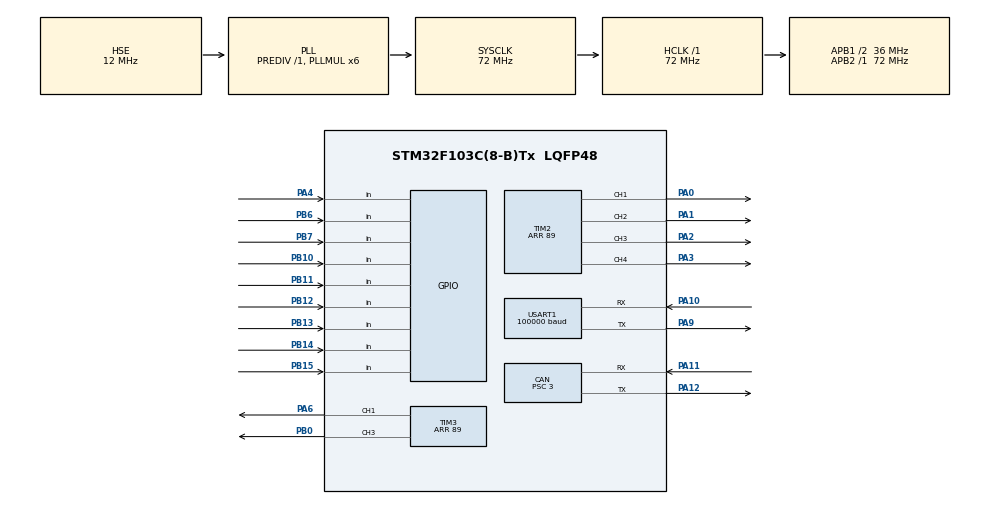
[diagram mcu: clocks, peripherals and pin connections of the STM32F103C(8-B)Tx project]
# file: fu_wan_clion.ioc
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CAN.BS1=CAN_BS1_9TQ
CAN.BS2=CAN_BS2_2TQ
CAN.CalculateBaudRate=999999
CAN.CalculateTimeBit=1000
CAN.CalculateTimeQuantum=83.33333333333334
CAN.Prescaler=3
Dma.Request0=TIM2_CH1
Dma.Request1=TIM2_CH2/CH4
Dma.Request2=TIM2_CH3
Dma.Request3=TIM3_CH1/TRIG
Dma.Request4=TIM3_CH3
Dma.TIM2_CH1.0.Direction=DMA_MEMORY_TO_PERIPH
Dma.TIM2_CH1.0.Instance=DMA1_Channel5
Dma.TIM2_CH1.0.MemDataAlignment=DMA_MDATAALIGN_HALFWORD
Dma.TIM2_CH1.0.MemInc=DMA_MINC_ENABLE
Dma.TIM2_CH1.0.Mode=DMA_NORMAL
Dma.TIM2_CH1.0.PeriphDataAlignment=DMA_PDATAALIGN_HALFWORD
Dma.TIM2_CH1.0.PeriphInc=DMA_PINC_DISABLE
Dma.TIM2_CH1.0.Priority=DMA_PRIORITY_LOW
Dma.TIM2_CH2/CH4.1.Direction=DMA_MEMORY_TO_PERIPH
Dma.TIM2_CH2/CH4.1.Instance=DMA1_Channel7
Dma.TIM2_CH2/CH4.1.MemDataAlignment=DMA_MDATAALIGN_HALFWORD
Dma.TIM2_CH2/CH4.1.MemInc=DMA_MINC_ENABLE
Dma.TIM2_CH2/CH4.1.Mode=DMA_NORMAL
Dma.TIM2_CH2/CH4.1.PeriphDataAlignment=DMA_PDATAALIGN_HALFWORD
Dma.TIM2_CH2/CH4.1.PeriphInc=DMA_PINC_DISABLE
Dma.TIM2_CH2/CH4.1.Priority=DMA_PRIORITY_LOW
Dma.TIM2_CH3.2.Direction=DMA_MEMORY_TO_PERIPH
Dma.TIM2_CH3.2.Instance=DMA1_Channel1
Dma.TIM2_CH3.2.MemDataAlignment=DMA_MDATAALIGN_HALFWORD
Dma.TIM2_CH3.2.MemInc=DMA_MINC_ENABLE
Dma.TIM2_CH3.2.Mode=DMA_NORMAL
Dma.TIM2_CH3.2.PeriphDataAlignment=DMA_PDATAALIGN_HALFWORD
Dma.TIM2_CH3.2.PeriphInc=DMA_PINC_DISABLE
Dma.TIM2_CH3.2.Priority=DMA_PRIORITY_LOW
Dma.TIM3_CH1/TRIG.3.Direction=DMA_MEMORY_TO_PERIPH
Dma.TIM3_CH1/TRIG.3.Instance=DMA1_Channel6
Dma.TIM3_CH1/TRIG.3.MemDataAlignment=DMA_MDATAALIGN_HALFWORD
Dma.TIM3_CH1/TRIG.3.MemInc=DMA_MINC_ENABLE
Dma.TIM3_CH1/TRIG.3.Mode=DMA_NORMAL
Dma.TIM3_CH1/TRIG.3.PeriphDataAlignment=DMA_PDATAALIGN_HALFWORD
Dma.TIM3_CH1/TRIG.3.PeriphInc=DMA_PINC_DISABLE
Dma.TIM3_CH1/TRIG.3.Priority=DMA_PRIORITY_LOW
Dma.TIM3_CH3.4.Direction=DMA_MEMORY_TO_PERIPH
Dma.TIM3_CH3.4.Instance=DMA1_Channel2
Dma.TIM3_CH3.4.MemDataAlignment=DMA_MDATAALIGN_HALFWORD
Dma.TIM3_CH3.4.MemInc=DMA_MINC_ENABLE
Dma.TIM3_CH3.4.Mode=DMA_NORMAL
Dma.TIM3_CH3.4.PeriphDataAlignment=DMA_PDATAALIGN_HALFWORD
Dma.TIM3_CH3.4.PeriphInc=DMA_PINC_DISABLE
Dma.TIM3_CH3.4.Priority=DMA_PRIORITY_LOW
Mcu.Family=STM32F1
Mcu.Name=STM32F103C(8-B)Tx
Mcu.Package=LQFP48
NVIC.DMA1_Channel1_IRQn=true\:0\:0\:false\:false\:true\:false\:true\:true
NVIC.DMA1_Channel2_IRQn=true\:0\:0\:false\:false\:true\:false\:true\:true
NVIC.DMA1_Channel5_IRQn=true\:0\:0\:false\:false\:true\:false\:true\:true
NVIC.DMA1_Channel6_IRQn=true\:0\:0\:false\:false\:true\:false\:true\:true
NVIC.DMA1_Channel7_IRQn=true\:0\:0\:false\:false\:true\:false\:true\:true
NVIC.PriorityGroup=NVIC_PRIORITYGROUP_4
NVIC.TIM4_IRQn=true\:0\:0\:false\:false\:true\:true\:true\:true
NVIC.USART1_IRQn=true\:0\:0\:false\:false\:true\:true\:true\:true
NVIC.USB_LP_CAN1_RX0_IRQn=true\:0\:0\:false\:false\:true\:true\:true\:true
PA0-WKUP.Signal=S_TIM2_CH1_ETR
PA1.Signal=S_TIM2_CH2
PA10.Mode=Asynchronous
PA10.Signal=USART1_RX
PA11.Mode=CAN_Activate
PA11.Signal=CAN_RX
PA12.Mode=CAN_Activate
PA12.Signal=CAN_TX
PA13.Mode=Serial_Wire
PA13.Signal=SYS_JTMS-SWDIO
PA14.Mode=Serial_Wire
PA14.Signal=SYS_JTCK-SWCLK
PA2.Signal=S_TIM2_CH3
PA3.Signal=S_TIM2_CH4
PA4.GPIO_PuPd=GPIO_PULLUP
PA4.Signal=GPIO_Input
PA6.Signal=S_TIM3_CH1
PA9.Mode=Asynchronous
PA9.Signal=USART1_TX
PB0.Signal=S_TIM3_CH3
PB10.GPIO_PuPd=GPIO_PULLUP
PB10.Signal=GPIO_Input
PB11.GPIO_PuPd=GPIO_PULLUP
PB11.Signal=GPIO_Input
PB12.GPIO_PuPd=GPIO_PULLUP
PB12.Signal=GPIO_Input
PB13.GPIO_PuPd=GPIO_PULLUP
PB13.Signal=GPIO_Input
PB14.GPIO_PuPd=GPIO_PULLUP
PB14.Signal=GPIO_Input
PB15.GPIO_PuPd=GPIO_PULLUP
PB15.Signal=GPIO_Input
PB6.GPIO_PuPd=GPIO_PULLUP
PB6.Signal=GPIO_Input
PB7.GPIO_PuPd=GPIO_PULLUP
PB7.Signal=GPIO_Input
PD0-OSC_IN.Mode=HSE-External-Oscillator
PD0-OSC_IN.Signal=RCC_OSC_IN
PD1-OSC_OUT.Mode=HSE-External-Oscillator
PD1-OSC_OUT.Signal=RCC_OSC_OUT
ProjectManager.HeapSize=0x200
ProjectManager.StackSize=0x400
ProjectManager.TargetToolchain=CMake
RCC.AHBFreq_Value=72000000
RCC.APB1CLKDivider=RCC_HCLK_DIV2
RCC.APB1Freq_Value=36000000
RCC.APB1TimFreq_Value=72000000
RCC.APB2Freq_Value=72000000
RCC.APB2TimFreq_Value=72000000
RCC.HCLKFreq_Value=72000000
RCC.HSE_VALUE=12000000
RCC.PLLMUL=RCC_PLL_MUL6
RCC.PLLSourceVirtual=RCC_PLLSOURCE_HSE
RCC.SYSCLKFreq_VALUE=72000000
RCC.SYSCLKSource=RCC_SYSCLKSOURCE_PLLCLK
RCC.USBFreq_Value=72000000
SH.S_TIM2_CH1_ETR.0=TIM2_CH1,PWM Generation1 CH1
SH.S_TIM2_CH2.0=TIM2_CH2,PWM Generation2 CH2
SH.S_TIM2_CH3.0=TIM2_CH3,PWM Generation3 CH3
SH.S_TIM2_CH4.0=TIM2_CH4,PWM Generation4 CH4
SH.S_TIM3_CH1.0=TIM3_CH1,PWM Generation1 CH1
SH.S_TIM3_CH3.0=TIM3_CH3,PWM Generation3 CH3
TIM2.Channel-PWM\ Generation1\ CH1=TIM_CHANNEL_1
TIM2.Channel-PWM\ Generation2\ CH2=TIM_CHANNEL_2
TIM2.Channel-PWM\ Generation3\ CH3=TIM_CHANNEL_3
TIM2.Channel-PWM\ Generation4\ CH4=TIM_CHANNEL_4
TIM2.Period=89
TIM3.Channel-PWM\ Generation1\ CH1=TIM_CHANNEL_1
TIM3.Channel-PWM\ Generation3\ CH3=TIM_CHANNEL_3
TIM3.Period=89
TIM4.Period=9
TIM4.Prescaler=7199
USART1.BaudRate=100000
USART1.Parity=PARITY_EVEN
USART1.VirtualMode=VM_ASYNC
USART1.WordLength=WORDLENGTH_9B
VP_TIM2_VS_ClockSourceINT.Mode=Internal
VP_TIM4_VS_ClockSourceINT.Mode=Internal
board=custom

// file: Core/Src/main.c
/* USER CODE BEGIN Header */
/**
  ******************************************************************************
  * @file           : main.c
  * @brief          : Main program body
  ******************************************************************************
  * @attention
  *
  * Copyright (c) 2026 STMicroelectronics.
  * All rights reserved.
  *
  * This software is licensed under terms that can be found in the LICENSE file
  * in the root directory of this software component.
  * If no LICENSE file comes with this software, it is provided AS-IS.
  *
  ******************************************************************************
  */
/* USER CODE END Header */
#include "main.h"
#include "can.h"
#include "dma.h"
#include "tim.h"
#include "usart.h"
#include "gpio.h"

/* USER CODE BEGIN Includes */
#include "energy_slave.h"
/* USER CODE END Includes */

void SystemClock_Config(void);

int main(void)
{

  /* MCU Configuration--------------------------------------------------------*/

  /* Reset of all peripherals, Initializes the Flash interface and the Systick. */
  HAL_Init();

  /* Configure the system clock */
  SystemClock_Config();

  /* Initialize all configured peripherals */
  MX_GPIO_Init();
  MX_DMA_Init();
  MX_CAN_Init();
  MX_TIM2_Init();
  MX_TIM3_Init();
  MX_TIM4_Init();
  MX_USART1_UART_Init();
  /* USER CODE BEGIN 2 */
  if (EnergySlave_Init() != HAL_OK)
  {
    Error_Handler();
  }
  /* USER CODE END 2 */

  /* Infinite loop */
  while (1)
  {

    /* USER CODE BEGIN 3 */
    EnergySlave_Update();
    HAL_Delay(1);
  }
  /* USER CODE END 3 */
}

void SystemClock_Config(void)
{
  RCC_OscInitTypeDef RCC_OscInitStruct = {0};
  RCC_ClkInitTypeDef RCC_ClkInitStruct = {0};

  /** Initializes the RCC Oscillators according to the specified parameters
  * in the RCC_OscInitTypeDef structure.
  */
  RCC_OscInitStruct.OscillatorType = RCC_OSCILLATORTYPE_HSE;
  RCC_OscInitStruct.HSEState = RCC_HSE_ON;
  RCC_OscInitStruct.HSEPredivValue = RCC_HSE_PREDIV_DIV1;
  RCC_OscInitStruct.HSIState = RCC_HSI_ON;
  RCC_OscInitStruct.PLL.PLLState = RCC_PLL_ON;
  RCC_OscInitStruct.PLL.PLLSource = RCC_PLLSOURCE_HSE;
  RCC_OscInitStruct.PLL.PLLMUL = RCC_PLL_MUL6; /* 12 MHz HSE x 6 = 72 MHz */
  if (HAL_RCC_OscConfig(&RCC_OscInitStruct) != HAL_OK)
  {
    Error_Handler();
  }

  /** Initializes the CPU, AHB and APB buses clocks
  */
  RCC_ClkInitStruct.ClockType = RCC_CLOCKTYPE_HCLK|RCC_CLOCKTYPE_SYSCLK
                              |RCC_CLOCKTYPE_PCLK1|RCC_CLOCKTYPE_PCLK2;
  RCC_ClkInitStruct.SYSCLKSource = RCC_SYSCLKSOURCE_PLLCLK;
  RCC_ClkInitStruct.AHBCLKDivider = RCC_SYSCLK_DIV1;
  RCC_ClkInitStruct.APB1CLKDivider = RCC_HCLK_DIV2;
  RCC_ClkInitStruct.APB2CLKDivider = RCC_HCLK_DIV1;

  if (HAL_RCC_ClockConfig(&RCC_ClkInitStruct, FLASH_LATENCY_2) != HAL_OK)
  {
    Error_Handler();
  }
}

/* USER CODE BEGIN 4 */
void HAL_TIM_PeriodElapsedCallback(TIM_HandleTypeDef *htim)
{
  if (htim->Instance == TIM4)
  {
    EnergySlave_1msTick();
  }
}
/* USER CODE END 4 */

void Error_Handler(void)
{
  __disable_irq();
  while (1)
  {
  }
}
